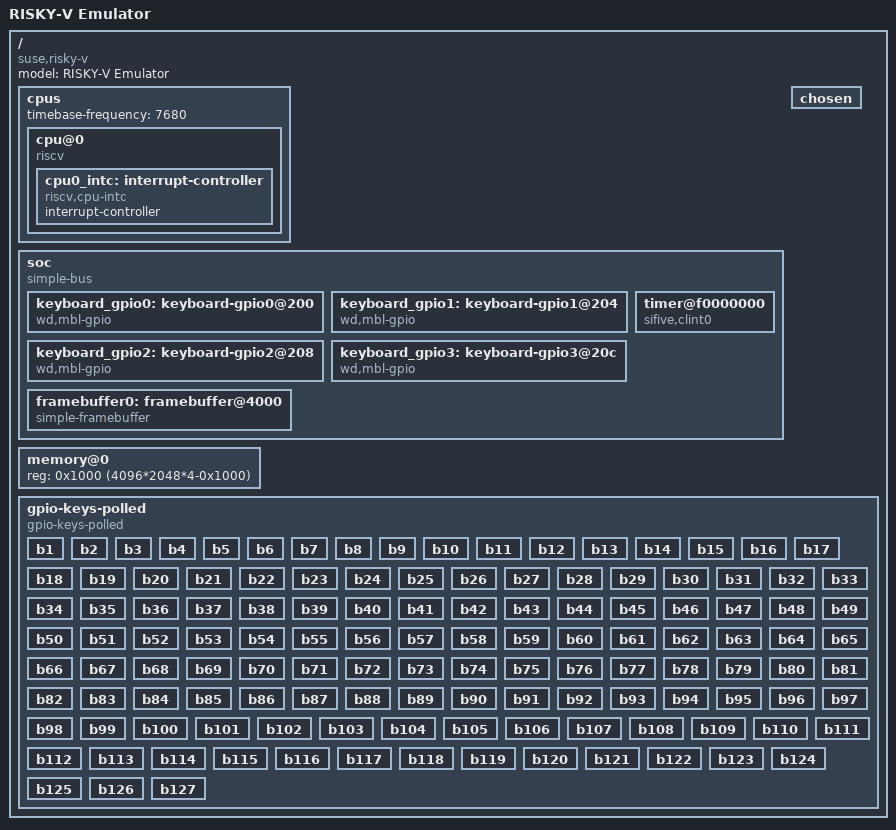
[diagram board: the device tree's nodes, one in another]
/dts-v1/;
/ {
	compatible = "suse,risky-v";
	model = "RISKY-V Emulator";
	#address-cells = <1>;
	#size-cells = <1>;

	cpus {
		#address-cells = <1>;
		#size-cells = <0>;
		/* 128 ticks per frame * 60 fps = 7680 ticks per second */
		timebase-frequency = <7680>;

		cpu@0 {
			reg = <0>;
			device_type = "cpu";
			compatible = "riscv";
			riscv,isa = "rv32ima_zicsr_zifencei";
			riscv,isa-base = "rv32i";
			riscv,isa-extensions = "i", "m", "a", "zicsr", "zifencei";

			cpu0_intc: interrupt-controller {
				#interrupt-cells = <1>;
				compatible = "riscv,cpu-intc";
				interrupt-controller;
			};
		};
	};

	soc {
		#address-cells = <1>;
		#size-cells = <1>;
		compatible = "simple-bus";
		ranges;

		keyboard_gpio0: keyboard-gpio0@200 {
			compatible = "wd,mbl-gpio";
			reg-names = "dat";
			reg = <0x200 0x4>;
			#gpio-cells = <2>;
			gpio-controller;
			no-output;
		};

		keyboard_gpio1: keyboard-gpio1@204 {
			compatible = "wd,mbl-gpio";
			reg-names = "dat";
			reg = <0x204 0x4>;
			#gpio-cells = <2>;
			gpio-controller;
			no-output;
		};

		keyboard_gpio2: keyboard-gpio2@208 {
			compatible = "wd,mbl-gpio";
			reg-names = "dat";
			reg = <0x208 0x4>;
			#gpio-cells = <2>;
			gpio-controller;
			no-output;
		};

		keyboard_gpio3: keyboard-gpio3@20c {
			compatible = "wd,mbl-gpio";
			reg-names = "dat";
			reg = <0x20c 0x4>;
			#gpio-cells = <2>;
			gpio-controller;
			no-output;
		};

		timer@f0000000 {
			compatible = "sifive,clint0";
			interrupts-extended = <&cpu0_intc 3>, <&cpu0_intc 7>;
			reg = <0xF0000000 0x10000>;
		};

		/* DTB is at 0x2000. Use 0x4000 to align with the memory texture. */
		framebuffer0: framebuffer@4000 {
			compatible = "simple-framebuffer";
			reg = <0x4000 0x12C000>;
			width = <640>;
			height = <480>;
			stride = <8192>;
			format = "x8r8g8b8";
		};
	};

	memory@0 {
		device_type = "memory";
		/* Until 0x1000 is private emulator state. */
		reg = <0x1000 (4096*2048*4-0x1000)>;
	};

	chosen {
		#address-cells = <1>;
		#size-cells = <1>;

		bootargs = "debug loglevel=9 earlycon=smh console=tty keep_bootcon";
	};

	gpio-keys-polled {
		compatible = "gpio-keys-polled";
		autorepeat;
		poll-interval = <16>;

		/* for i in $(seq 1 127); do printf '\t\tb%d { linux,code = <%d>; gpios = <&keyboard_gpio%d %d 0>; };\n' $i $i $(($i / 32)) $(($i % 32)); done */
		b1 { linux,code = <1>; gpios = <&keyboard_gpio0 1 0>; };
		b2 { linux,code = <2>; gpios = <&keyboard_gpio0 2 0>; };
		b3 { linux,code = <3>; gpios = <&keyboard_gpio0 3 0>; };
		b4 { linux,code = <4>; gpios = <&keyboard_gpio0 4 0>; };
		b5 { linux,code = <5>; gpios = <&keyboard_gpio0 5 0>; };
		b6 { linux,code = <6>; gpios = <&keyboard_gpio0 6 0>; };
		b7 { linux,code = <7>; gpios = <&keyboard_gpio0 7 0>; };
		b8 { linux,code = <8>; gpios = <&keyboard_gpio0 8 0>; };
		b9 { linux,code = <9>; gpios = <&keyboard_gpio0 9 0>; };
		b10 { linux,code = <10>; gpios = <&keyboard_gpio0 10 0>; };
		b11 { linux,code = <11>; gpios = <&keyboard_gpio0 11 0>; };
		b12 { linux,code = <12>; gpios = <&keyboard_gpio0 12 0>; };
		b13 { linux,code = <13>; gpios = <&keyboard_gpio0 13 0>; };
		b14 { linux,code = <14>; gpios = <&keyboard_gpio0 14 0>; };
		b15 { linux,code = <15>; gpios = <&keyboard_gpio0 15 0>; };
		b16 { linux,code = <16>; gpios = <&keyboard_gpio0 16 0>; };
		b17 { linux,code = <17>; gpios = <&keyboard_gpio0 17 0>; };
		b18 { linux,code = <18>; gpios = <&keyboard_gpio0 18 0>; };
		b19 { linux,code = <19>; gpios = <&keyboard_gpio0 19 0>; };
		b20 { linux,code = <20>; gpios = <&keyboard_gpio0 20 0>; };
		b21 { linux,code = <21>; gpios = <&keyboard_gpio0 21 0>; };
		b22 { linux,code = <22>; gpios = <&keyboard_gpio0 22 0>; };
		b23 { linux,code = <23>; gpios = <&keyboard_gpio0 23 0>; };
		b24 { linux,code = <24>; gpios = <&keyboard_gpio0 24 0>; };
		b25 { linux,code = <25>; gpios = <&keyboard_gpio0 25 0>; };
		b26 { linux,code = <26>; gpios = <&keyboard_gpio0 26 0>; };
		b27 { linux,code = <27>; gpios = <&keyboard_gpio0 27 0>; };
		b28 { linux,code = <28>; gpios = <&keyboard_gpio0 28 0>; };
		b29 { linux,code = <29>; gpios = <&keyboard_gpio0 29 0>; };
		b30 { linux,code = <30>; gpios = <&keyboard_gpio0 30 0>; };
		b31 { linux,code = <31>; gpios = <&keyboard_gpio0 31 0>; };
		b32 { linux,code = <32>; gpios = <&keyboard_gpio1 0 0>; };
		b33 { linux,code = <33>; gpios = <&keyboard_gpio1 1 0>; };
		b34 { linux,code = <34>; gpios = <&keyboard_gpio1 2 0>; };
		b35 { linux,code = <35>; gpios = <&keyboard_gpio1 3 0>; };
		b36 { linux,code = <36>; gpios = <&keyboard_gpio1 4 0>; };
		b37 { linux,code = <37>; gpios = <&keyboard_gpio1 5 0>; };
		b38 { linux,code = <38>; gpios = <&keyboard_gpio1 6 0>; };
		b39 { linux,code = <39>; gpios = <&keyboard_gpio1 7 0>; };
		b40 { linux,code = <40>; gpios = <&keyboard_gpio1 8 0>; };
		b41 { linux,code = <41>; gpios = <&keyboard_gpio1 9 0>; };
		b42 { linux,code = <42>; gpios = <&keyboard_gpio1 10 0>; };
		b43 { linux,code = <43>; gpios = <&keyboard_gpio1 11 0>; };
		b44 { linux,code = <44>; gpios = <&keyboard_gpio1 12 0>; };
		b45 { linux,code = <45>; gpios = <&keyboard_gpio1 13 0>; };
		b46 { linux,code = <46>; gpios = <&keyboard_gpio1 14 0>; };
		b47 { linux,code = <47>; gpios = <&keyboard_gpio1 15 0>; };
		b48 { linux,code = <48>; gpios = <&keyboard_gpio1 16 0>; };
		b49 { linux,code = <49>; gpios = <&keyboard_gpio1 17 0>; };
		b50 { linux,code = <50>; gpios = <&keyboard_gpio1 18 0>; };
		b51 { linux,code = <51>; gpios = <&keyboard_gpio1 19 0>; };
		b52 { linux,code = <52>; gpios = <&keyboard_gpio1 20 0>; };
		b53 { linux,code = <53>; gpios = <&keyboard_gpio1 21 0>; };
		b54 { linux,code = <54>; gpios = <&keyboard_gpio1 22 0>; };
		b55 { linux,code = <55>; gpios = <&keyboard_gpio1 23 0>; };
		b56 { linux,code = <56>; gpios = <&keyboard_gpio1 24 0>; };
		b57 { linux,code = <57>; gpios = <&keyboard_gpio1 25 0>; };
		b58 { linux,code = <58>; gpios = <&keyboard_gpio1 26 0>; };
		b59 { linux,code = <59>; gpios = <&keyboard_gpio1 27 0>; };
		b60 { linux,code = <60>; gpios = <&keyboard_gpio1 28 0>; };
		b61 { linux,code = <61>; gpios = <&keyboard_gpio1 29 0>; };
		b62 { linux,code = <62>; gpios = <&keyboard_gpio1 30 0>; };
		b63 { linux,code = <63>; gpios = <&keyboard_gpio1 31 0>; };
		b64 { linux,code = <64>; gpios = <&keyboard_gpio2 0 0>; };
		b65 { linux,code = <65>; gpios = <&keyboard_gpio2 1 0>; };
		b66 { linux,code = <66>; gpios = <&keyboard_gpio2 2 0>; };
		b67 { linux,code = <67>; gpios = <&keyboard_gpio2 3 0>; };
		b68 { linux,code = <68>; gpios = <&keyboard_gpio2 4 0>; };
		b69 { linux,code = <69>; gpios = <&keyboard_gpio2 5 0>; };
		b70 { linux,code = <70>; gpios = <&keyboard_gpio2 6 0>; };
		b71 { linux,code = <71>; gpios = <&keyboard_gpio2 7 0>; };
		b72 { linux,code = <72>; gpios = <&keyboard_gpio2 8 0>; };
		b73 { linux,code = <73>; gpios = <&keyboard_gpio2 9 0>; };
		b74 { linux,code = <74>; gpios = <&keyboard_gpio2 10 0>; };
		b75 { linux,code = <75>; gpios = <&keyboard_gpio2 11 0>; };
		b76 { linux,code = <76>; gpios = <&keyboard_gpio2 12 0>; };
		b77 { linux,code = <77>; gpios = <&keyboard_gpio2 13 0>; };
		b78 { linux,code = <78>; gpios = <&keyboard_gpio2 14 0>; };
		b79 { linux,code = <79>; gpios = <&keyboard_gpio2 15 0>; };
		b80 { linux,code = <80>; gpios = <&keyboard_gpio2 16 0>; };
		b81 { linux,code = <81>; gpios = <&keyboard_gpio2 17 0>; };
		b82 { linux,code = <82>; gpios = <&keyboard_gpio2 18 0>; };
		b83 { linux,code = <83>; gpios = <&keyboard_gpio2 19 0>; };
		b84 { linux,code = <84>; gpios = <&keyboard_gpio2 20 0>; };
		b85 { linux,code = <85>; gpios = <&keyboard_gpio2 21 0>; };
		b86 { linux,code = <86>; gpios = <&keyboard_gpio2 22 0>; };
		b87 { linux,code = <87>; gpios = <&keyboard_gpio2 23 0>; };
		b88 { linux,code = <88>; gpios = <&keyboard_gpio2 24 0>; };
		b89 { linux,code = <89>; gpios = <&keyboard_gpio2 25 0>; };
		b90 { linux,code = <90>; gpios = <&keyboard_gpio2 26 0>; };
		b91 { linux,code = <91>; gpios = <&keyboard_gpio2 27 0>; };
		b92 { linux,code = <92>; gpios = <&keyboard_gpio2 28 0>; };
		b93 { linux,code = <93>; gpios = <&keyboard_gpio2 29 0>; };
		b94 { linux,code = <94>; gpios = <&keyboard_gpio2 30 0>; };
		b95 { linux,code = <95>; gpios = <&keyboard_gpio2 31 0>; };
		b96 { linux,code = <96>; gpios = <&keyboard_gpio3 0 0>; };
		b97 { linux,code = <97>; gpios = <&keyboard_gpio3 1 0>; };
		b98 { linux,code = <98>; gpios = <&keyboard_gpio3 2 0>; };
		b99 { linux,code = <99>; gpios = <&keyboard_gpio3 3 0>; };
		b100 { linux,code = <100>; gpios = <&keyboard_gpio3 4 0>; };
		b101 { linux,code = <101>; gpios = <&keyboard_gpio3 5 0>; };
		b102 { linux,code = <102>; gpios = <&keyboard_gpio3 6 0>; };
		b103 { linux,code = <103>; gpios = <&keyboard_gpio3 7 0>; };
		b104 { linux,code = <104>; gpios = <&keyboard_gpio3 8 0>; };
		b105 { linux,code = <105>; gpios = <&keyboard_gpio3 9 0>; };
		b106 { linux,code = <106>; gpios = <&keyboard_gpio3 10 0>; };
		b107 { linux,code = <107>; gpios = <&keyboard_gpio3 11 0>; };
		b108 { linux,code = <108>; gpios = <&keyboard_gpio3 12 0>; };
		b109 { linux,code = <109>; gpios = <&keyboard_gpio3 13 0>; };
		b110 { linux,code = <110>; gpios = <&keyboard_gpio3 14 0>; };
		b111 { linux,code = <111>; gpios = <&keyboard_gpio3 15 0>; };
		b112 { linux,code = <112>; gpios = <&keyboard_gpio3 16 0>; };
		b113 { linux,code = <113>; gpios = <&keyboard_gpio3 17 0>; };
		b114 { linux,code = <114>; gpios = <&keyboard_gpio3 18 0>; };
		b115 { linux,code = <115>; gpios = <&keyboard_gpio3 19 0>; };
		b116 { linux,code = <116>; gpios = <&keyboard_gpio3 20 0>; };
		b117 { linux,code = <117>; gpios = <&keyboard_gpio3 21 0>; };
		b118 { linux,code = <118>; gpios = <&keyboard_gpio3 22 0>; };
		b119 { linux,code = <119>; gpios = <&keyboard_gpio3 23 0>; };
		b120 { linux,code = <120>; gpios = <&keyboard_gpio3 24 0>; };
		b121 { linux,code = <121>; gpios = <&keyboard_gpio3 25 0>; };
		b122 { linux,code = <122>; gpios = <&keyboard_gpio3 26 0>; };
		b123 { linux,code = <123>; gpios = <&keyboard_gpio3 27 0>; };
		b124 { linux,code = <124>; gpios = <&keyboard_gpio3 28 0>; };
		b125 { linux,code = <125>; gpios = <&keyboard_gpio3 29 0>; };
		b126 { linux,code = <126>; gpios = <&keyboard_gpio3 30 0>; };
		b127 { linux,code = <127>; gpios = <&keyboard_gpio3 31 0>; };
	};
};
